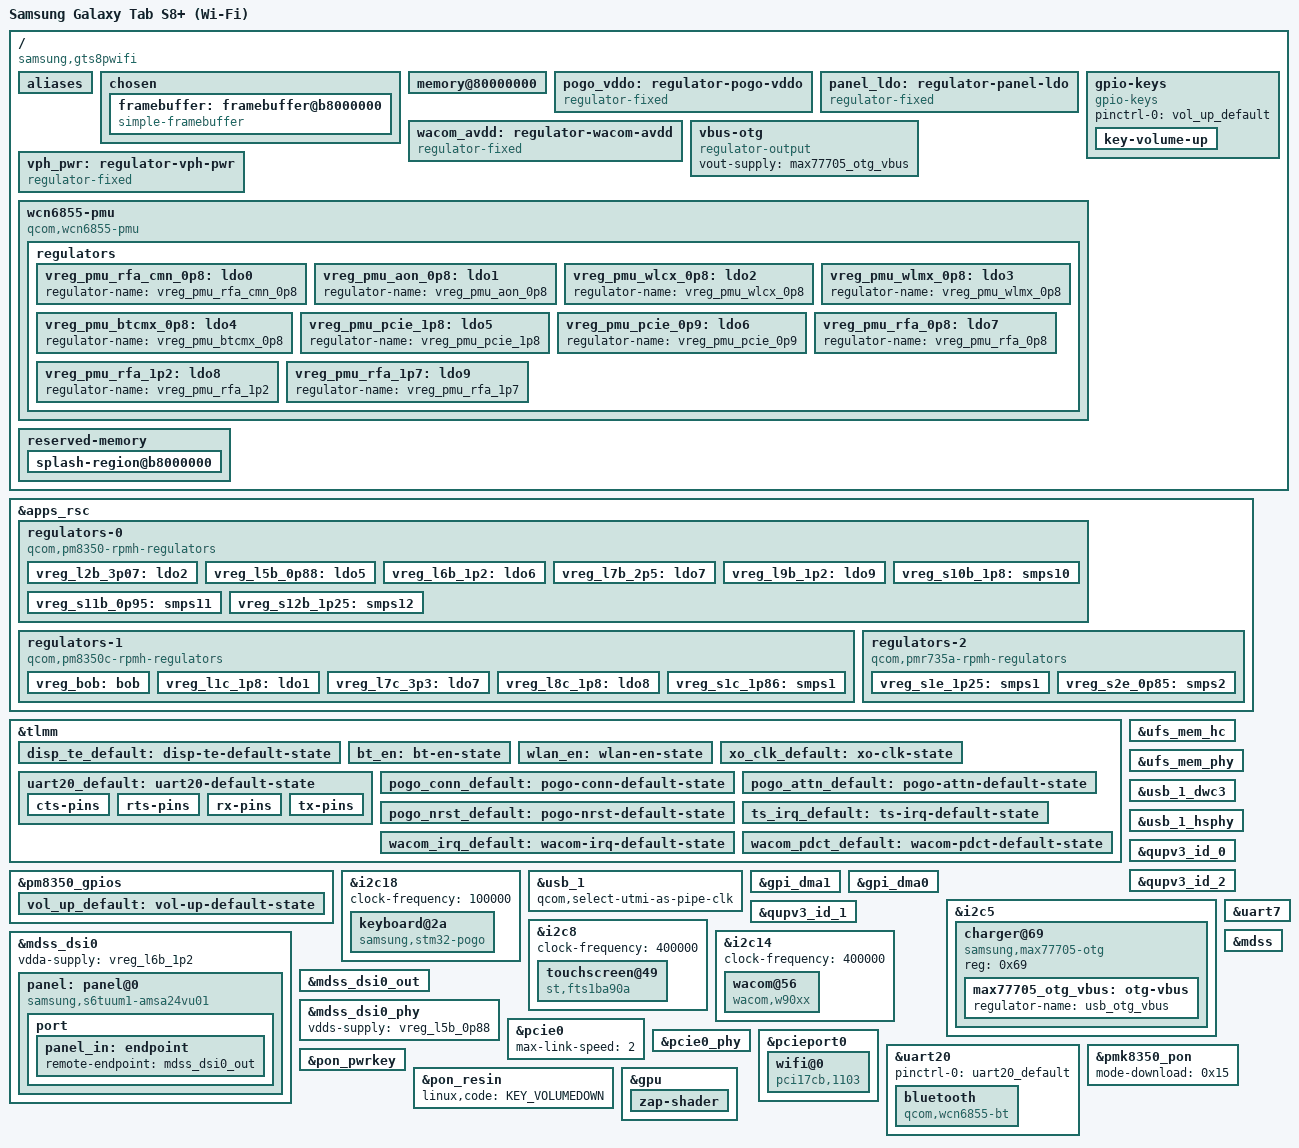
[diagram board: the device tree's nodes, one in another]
// SPDX-License-Identifier: GPL-2.0-only
/*
 * Samsung Galaxy Tab S8+ Wi-Fi (SM-X800), codename "gts8pwifi".
 *
 * SM8450 (Waipio). First-boot bring-up skeleton derived from
 * sm8450-samsung-r0q.dts (Galaxy S22). The bootloader (Samsung ABL)
 * leaves the panel scanning out of the "splash_region" at 0xb8000000,
 * so a matching simple-framebuffer node gives us a VISIBLE fbcon console
 * on the panel before any real DRM driver exists. This is the whole
 * point of the mainline pivot (see docs/discovery-notes/04-mainline-prep.md).
 *
 * Framebuffer geometry pulled from the stock DTB:
 *   splash reserved-memory  = <0x0 0xb8000000 0x0 0x2b00000> (45 MiB)
 *   panel active (touch max) = 1752 x 2800 (0x6d8 x 0xaf0), portrait scanout
 *   DDIC S6TUUM1_AMSA24VU01_WQXGA, lcd_id 800005 (native driver = later)
 */

/dts-v1/;

#include <dt-bindings/gpio/gpio.h>
#include <dt-bindings/input/linux-event-codes.h>
#include <dt-bindings/interrupt-controller/irq.h>
#include <dt-bindings/regulator/qcom,rpmh-regulator.h>

#include "sm8450.dtsi"
#include "pm8350.dtsi"
#include "pm8350c.dtsi"
/* pmk8350 carries the power key + resin (volume down) — see &pon_* below */
#include "pmk8350.dtsi"

/ {
	model = "Samsung Galaxy Tab S8+ (Wi-Fi)";
	compatible = "samsung,gts8pwifi", "qcom,sm8450";
	chassis-type = "tablet";

	/*
	 * Samsung's Qualcomm bootloader (ABL) runs DTB selection: it only
	 * boots a DTB whose qcom,msm-id (SoC id+rev) and qcom,board-id match
	 * the running hardware. Mainline DTs omit these, so ABL found no match
	 * and jumped to the kernel with no device tree -> early death, no
	 * simplefb, fall back to download mode. These values are copied
	 * verbatim from the stock DTB (device-facts/dt/stock-fdt.dtb). The
	 * kernel ignores them; they exist purely for the bootloader.
	 */
	qcom,msm-id = <0x1c9 0x10000>, <0x1e2 0x10000>;
	qcom,board-id = <0x10008 0x04>;

	/*
	 * qcom_geni_serial derives its tty line number from these aliases and
	 * fails probe with "Invalid line -19" without one. That silently broke
	 * BOTH uarts: uart7 (debug, has been failing since bring-up — earlycon
	 * worked because it bypasses the tty layer) and uart20, whose failed
	 * probe also held four interconnect providers' sync_state() hostage
	 * (the i2c8 lesson again) and kept the wcn6855-bt serdev child from
	 * ever binding.
	 */
	aliases {
		serial0 = &uart7;
		serial1 = &uart20;
	};

	chosen {
		#address-cells = <2>;
		#size-cells = <2>;
		ranges;

		/*
		 * We boot via uniLoader (the Samsung ABL mangles mainline DTs
		 * with its own DTBO fragments, so a direct ABL boot cannot
		 * work here — see docs/05). uniLoader only injects
		 * linux,initrd-start/end into /chosen; it does NOT set
		 * bootargs. So the kernel command line has to live here, or we
		 * would silently inherit the stock vendor_boot cmdline
		 * (console=null) and be blind again.
		 *
		 * LAYOUT: userdata holds the COMBINED pmOS image (`pmb install`
		 * WITHOUT --split), i.e. a GPT containing BOTH pmOS_boot and
		 * pmOS_root as "subpartitions". That is required: the pmOS
		 * initramfs does mount_subpartitions -> wait_boot_partition ->
		 * mount_boot_partition, so it needs a pmOS_boot too, and our
		 * real boot partition is occupied by uniLoader. Flashing only
		 * the --split -root.img leaves no boot partition and the
		 * initramfs falls to the debug shell.
		 *
		 * Both UUIDs must match the image actually flashed to userdata.
		 * NOTE: re-running `pmb install` regenerates them — read the
		 * fresh values out of boot-deploy's cmdline:
		 *   strings <pmb-work>/chroot_rootfs_<device>/boot/vendor_boot.img
		 *     | grep pmos_root_uuid
		 */
		/*
		 * NOTE: console=ttyMSM0 was REMOVED. uart7 is enabled (so the
		 * port exists and earlycon still works), but with no cable
		 * attached its RX line floats and picks up noise. getty reads
		 * that noise as input and re-prints the login prompt forever,
		 * which also corrupts the framebuffer console we actually use.
		 * Put console=ttyMSM0,115200n8 back only when something is
		 * physically wired to the UART.
		 *
		 * clk_ignore_unused / pd_ignore_unused are REQUIRED to keep the
		 * panel alive. The bootloader leaves the display clocks and
		 * power domains running so the cont_splash framebuffer keeps
		 * scanning out. Late in boot the kernel disables everything it
		 * believes is unused — there is no real display driver here to
		 * claim them — which gates the display clocks and the panel
		 * goes BLACK mid-boot, even though the kernel is still running
		 * happily. Observed exactly that: boot log painted, then black.
		 */
		/*
		 * r40: clk_ignore_unused / pd_ignore_unused RETIRED. They were
		 * required in the simpledrm era (see the note above — nothing
		 * claimed the display clocks). Now the msm DPU/DSI/panel and
		 * GPU drivers own their clocks and domains; keeping every
		 * unclaimed clock/GDSC on forever costs power and masks real
		 * PM bugs. If this boot regresses, the failing subsystem is
		 * whatever still lacks a driver to claim its resources.
		 */
		/*
		 * r41: loglevel=8 ignore_loglevel -> loglevel=4. Bring-up-era
		 * verbosity put EVERY printk on the panel; in steady state the
		 * wlan0 chatter alone stomped agetty into endlessly re-printing
		 * "login:" (photo-verified). Warnings and errors still reach
		 * the console; everything lands in the persistent journal.
		 */
		bootargs = "earlycon=qcom_geni,0x0099c000 console=tty0 fbcon=font:TER16x32 loglevel=4 arm-smmu.disable_bypass=0 PMOS_NO_OUTPUT_REDIRECT pmos_boot_uuid=a52ecfd9-ba7c-4c8e-a80f-d6341ef93081 pmos_root_uuid=ae56a720-d465-46c7-9e43-ecbd33124aa9 pmos_rootfsopts=defaults";

		framebuffer: framebuffer@b8000000 {
			compatible = "simple-framebuffer";
			reg = <0x0 0xb8000000 0x0 0x2b00000>;
			/*
			 * LANDSCAPE scanout: 2800 wide x 1752 tall. Confirmed
			 * on-device — using 1752x2800 rendered diagonally
			 * sheared text. Stock panel physical size is
			 * 267mm x 167mm (ratio 1.60 == 2800/1752), so the long
			 * axis is the scanline. The touchscreen's
			 * sec,max_coords <0x6d8 0xaf0> is a portrait touch
			 * coordinate space and does NOT describe scanout.
			 */
			width = <2800>;
			height = <1752>;
			stride = <(2800 * 4)>;
			format = "a8r8g8b8";

			/*
			 * simpledrm acquires and HOLDS these across boot (see
			 * simpledrm_device_release_clocks / _detach_genpd in
			 * the kernel). Without them nothing keeps the display
			 * block alive: the bootloader's scanout gets torn down
			 * and the framebuffer degenerates into ordinary RAM,
			 * which renders on-panel as accumulating garbage.
			 * Clock/GDSC references taken from the mdss node in
			 * mainline sm8450.dtsi.
			 */
			clocks = <&dispcc DISP_CC_MDSS_AHB_CLK>,
				 <&gcc GCC_DISP_HF_AXI_CLK>,
				 <&gcc GCC_DISP_SF_AXI_CLK>,
				 <&dispcc DISP_CC_MDSS_MDP_CLK>,
				 <&dispcc DISP_CC_MDSS_VSYNC_CLK>;
			power-domains = <&dispcc MDSS_GDSC>;
		};
	};

	/*
	 * sm8450.dtsi ships a placeholder memory@a0000000 with reg size 0,
	 * on the assumption that the bootloader patches in the real banks.
	 * uniLoader does NOT do that (it only injects linux,initrd-start/end
	 * into /chosen), so the kernel would be handed ZERO bytes of RAM and
	 * panic instantly, before any console exists — a completely silent
	 * hang right after uniLoader prints "Booting kernel...".
	 *
	 * Banks copied verbatim from the stock DTB (device-facts/dt/stock-fdt.dtb),
	 * total 8 GiB.
	 */
	/delete-node/ memory@a0000000;

	memory@80000000 {
		device_type = "memory";
		reg = <0x0 0x80000000 0x0 0x6a000000>,
		      <0x0 0xf1c00000 0x0 0x0e400000>,
		      <0x8 0x00000000 0x0 0x3ab00000>,
		      <0x8 0x40000000 0x1 0x40000000>,
		      <0x8 0x3b100000 0x0 0x01e00000>;
	};

	/*
	 * Pogo/Book-Cover-Keyboard STM32 supply. Stock models this as a plain
	 * GPIO-switched fixed regulator (not a PMIC rail): gpio70, active high.
	 * Gated by the stm32-pogo driver: on at dock, off at detach — always-on
	 * was a bring-up crutch and is gone now that the driver owns the rail.
	 */
	pogo_vddo: regulator-pogo-vddo {
		compatible = "regulator-fixed";
		regulator-name = "pogo_vddo";
		gpio = <&tlmm 70 GPIO_ACTIVE_HIGH>;
		enable-active-high;
	};

	/*
	 * Panel power. Stock models the OLED's supply as a GPIO-switched
	 * external LDO (fixed_regulator@1 "panel_ldo_en", tlmm 34), boot-on —
	 * which is why the bootloader splash survives to this day. The panel
	 * driver consumes it as vdd; boot-on keeps the handoff glitch-free.
	 */
	panel_ldo: regulator-panel-ldo {
		compatible = "regulator-fixed";
		regulator-name = "panel_ldo_en";
		gpio = <&tlmm 34 GPIO_ACTIVE_HIGH>;
		enable-active-high;
		regulator-boot-on;
	};

	/*
	 * S Pen (Wacom W90xx EMR digitizer) AVDD. Stock models it as a
	 * GPIO-switched fixed regulator (fixed_regulator0, tlmm 167, active
	 * high). regulator-always-on for now: the pen has no mainline driver
	 * yet, so nothing else would enable the rail — always-on lets the chip
	 * power up so its i2c presence (0x56 on &i2c14) can be probed. Once a
	 * wacom driver lands it should own this rail (drop always-on), the way
	 * the stm32-pogo driver took over pogo_vddo.
	 */
	wacom_avdd: regulator-wacom-avdd {
		compatible = "regulator-fixed";
		regulator-name = "wacom_avdd";
		gpio = <&tlmm 167 GPIO_ACTIVE_HIGH>;
		enable-active-high;
		regulator-always-on;
		regulator-boot-on;
	};

	/*
	 * Manual switch for tablet-sourced USB VBUS (the MAX77705 OTG boost,
	 * see charger@69). regulator-output is the mainline convention for a
	 * userspace-switched rail: it surfaces
	 *     /sys/devices/platform/vbus-otg/state
	 * (helper: `vbus-otg on|off`). Default off; the driver refuses to
	 * enable while a charger input is present. Automatic switching is
	 * Type-C/TCPM territory — a later increment.
	 */
	vbus-otg {
		compatible = "regulator-output";
		vout-supply = <&max77705_otg_vbus>;
	};

	/*
	 * Volume UP + pogo attach detection.
	 *
	 * Volume up is the odd one out on this device: power and volume-DOWN
	 * live in the pmk8350 PON block (&pon_pwrkey / &pon_resin), but stock
	 * wires volume-UP as a plain gpio-keys line on a pm8350 PMIC GPIO,
	 * active LOW with a pull-up. Stock DTB:
	 *     vol_up { gpios = <0x540 0x06 0x01>; linux,code = <0x73>; }
	 * where phandle 0x540 is qcom,pm8350-gpio @0x8800 and 0x01 = ACTIVE_LOW.
	 *
	 * STATUS: dead, and NOT an index problem. Measured on-device (r38,
	 * 2026-07-20): with gpio-keys unbound, gpiomon watched every line of
	 * pm8350/pm8350c/pmk8350 through repeated vol-up presses — zero edges
	 * anywhere. Line 5 (= this cell 6) idles high like a pulled-up button
	 * but never drops on press. Stock DTB has exactly one vol-up wiring
	 * (this one), so the next step is schematic-level: check the pull-up
	 * power-source rail, or poke the pm8350 gpio6 status register over
	 * SPMI debugfs while pressing. Do NOT bother permuting cell numbers;
	 * that experiment is done.
	 */
	gpio-keys {
		compatible = "gpio-keys";
		pinctrl-names = "default";
		pinctrl-0 = <&vol_up_default>;

		key-volume-up {
			label = "Volume Up";
			gpios = <&pm8350_gpios 6 GPIO_ACTIVE_LOW>;
			linux,code = <KEY_VOLUMEUP>;
			debounce-interval = <15>;
			wakeup-source;
		};

		/*
		 * The switch-pogo-attach EV_SW debug node that used to live
		 * here is gone: the stm32-pogo driver now owns tlmm gpio59 as
		 * its connection interrupt (a GPIO cannot be claimed by both).
		 * The pogo pinctrl states moved to the keyboard@2a node with
		 * it.
		 */
	};

	vph_pwr: regulator-vph-pwr {
		compatible = "regulator-fixed";
		regulator-name = "vph_pwr";
		regulator-min-microvolt = <3700000>;
		regulator-max-microvolt = <3700000>;
		regulator-always-on;
		regulator-boot-on;
	};

	/*
	 * WiFi/BT: QCA6490 (= WCN6855 family), WiFi on PCIe0 via ath11k, BT
	 * on uart20. Near-copy of sm8450-hdk.dts, and legitimately so: the
	 * stock DTB's cnss-qca6490/bt_qca6490 nodes use the exact same
	 * enable GPIOs (wlan 80, bt 81, sw-ctrl 82, xo-clk 204) and the same
	 * PMIC rails as the HDK — both boards follow the QC reference
	 * design. Rail cross-check stock -> mainline:
	 *   vdd-wlan-io   pm8350_s10  1.8 V   -> vddio   (vreg_s10b_1p8)
	 *   vdd-wlan-dig  pm8350_s11  0.966 V -> vddaon/vddpmucx/vddrfa0p95
	 *   vdd-wlan-rfa1 pm8350c_s1  1.9-2.1 -> vddrfa1p9 (vreg_s1c_1p86)
	 *   vdd-wlan-rfa2 pm8350_s12  1.35 V  -> vddrfa1p3 (vreg_s12b_1p25)
	 *   vdd-wlan-aon  pmr735a_s2  1.012 V -> vddpmumx  (vreg_s2e_0p85)
	 * Stock also lists a wlan-ant-switch supply (pmr735a_l7, 2.8 V), but
	 * there is no physical antenna switch on this tablet (owner-confirmed)
	 * — a copy-paste from the QC reference DT. Deliberately not wired; do
	 * not chase it for RF issues.
	 */
	wcn6855-pmu {
		compatible = "qcom,wcn6855-pmu";

		pinctrl-0 = <&bt_en>, <&wlan_en>, <&xo_clk_default>;
		pinctrl-names = "default";

		wlan-enable-gpios = <&tlmm 80 GPIO_ACTIVE_HIGH>;
		bt-enable-gpios = <&tlmm 81 GPIO_ACTIVE_HIGH>;
		swctrl-gpios = <&tlmm 82 GPIO_ACTIVE_HIGH>;
		xo-clk-gpios = <&tlmm 204 GPIO_ACTIVE_HIGH>;

		vddio-supply = <&vreg_s10b_1p8>;
		vddaon-supply = <&vreg_s11b_0p95>;
		vddpmu-supply = <&vreg_s12b_1p25>;
		vddpmumx-supply = <&vreg_s2e_0p85>;
		vddpmucx-supply = <&vreg_s11b_0p95>;
		vddrfa0p95-supply = <&vreg_s11b_0p95>;
		vddrfa1p3-supply = <&vreg_s12b_1p25>;
		vddrfa1p9-supply = <&vreg_s1c_1p86>;
		vddpcie1p3-supply = <&vreg_s12b_1p25>;
		vddpcie1p9-supply = <&vreg_s1c_1p86>;

		regulators {
			vreg_pmu_rfa_cmn_0p8: ldo0 {
				regulator-name = "vreg_pmu_rfa_cmn_0p8";
			};

			vreg_pmu_aon_0p8: ldo1 {
				regulator-name = "vreg_pmu_aon_0p8";
			};

			vreg_pmu_wlcx_0p8: ldo2 {
				regulator-name = "vreg_pmu_wlcx_0p8";
			};

			vreg_pmu_wlmx_0p8: ldo3 {
				regulator-name = "vreg_pmu_wlmx_0p8";
			};

			vreg_pmu_btcmx_0p8: ldo4 {
				regulator-name = "vreg_pmu_btcmx_0p8";
			};

			vreg_pmu_pcie_1p8: ldo5 {
				regulator-name = "vreg_pmu_pcie_1p8";
			};

			vreg_pmu_pcie_0p9: ldo6 {
				regulator-name = "vreg_pmu_pcie_0p9";
			};

			vreg_pmu_rfa_0p8: ldo7 {
				regulator-name = "vreg_pmu_rfa_0p8";
			};

			vreg_pmu_rfa_1p2: ldo8 {
				regulator-name = "vreg_pmu_rfa_1p2";
			};

			vreg_pmu_rfa_1p7: ldo9 {
				regulator-name = "vreg_pmu_rfa_1p7";
			};
		};
	};

	reserved-memory {
		/*
		 * The bootloader will only keep display hardware enabled
		 * if this memory region is named exactly 'splash_region'
		 */
		splash-region@b8000000 {
			reg = <0x0 0xb8000000 0x0 0x2b00000>;
			no-map;
		};
	};
};

&apps_rsc {
	regulators-0 {
		compatible = "qcom,pm8350-rpmh-regulators";
		qcom,pmic-id = "b";

		vdd-s1-supply = <&vph_pwr>;
		vdd-s2-supply = <&vph_pwr>;
		vdd-s3-supply = <&vph_pwr>;
		vdd-s4-supply = <&vph_pwr>;
		vdd-s5-supply = <&vph_pwr>;
		vdd-s6-supply = <&vph_pwr>;
		vdd-s7-supply = <&vph_pwr>;
		vdd-s8-supply = <&vph_pwr>;
		vdd-s9-supply = <&vph_pwr>;
		vdd-s10-supply = <&vph_pwr>;
		vdd-s11-supply = <&vph_pwr>;
		vdd-s12-supply = <&vph_pwr>;

		vdd-l2-l7-supply = <&vreg_bob>;
		vdd-l3-l5-supply = <&vreg_bob>;
		vdd-l6-l9-l11-supply = <&vreg_bob>;

		vreg_l2b_3p07: ldo2 {
			regulator-min-microvolt = <3072000>;
			regulator-max-microvolt = <3072000>;
			regulator-initial-mode = <RPMH_REGULATOR_MODE_HPM>;
		};

		vreg_l5b_0p88: ldo5 {
			regulator-min-microvolt = <880000>;
			regulator-max-microvolt = <888000>;
			regulator-initial-mode = <RPMH_REGULATOR_MODE_HPM>;
		};

		/* UFS rails (l6b/l7b/l9b) — see &ufs_mem_hc below */
		vreg_l6b_1p2: ldo6 {
			regulator-name = "vreg_l6b_1p2";
			regulator-min-microvolt = <1200000>;
			regulator-max-microvolt = <1200000>;
			regulator-initial-mode = <RPMH_REGULATOR_MODE_HPM>;
		};

		vreg_l7b_2p5: ldo7 {
			regulator-name = "vreg_l7b_2p5";
			regulator-min-microvolt = <2504000>;
			regulator-max-microvolt = <2504000>;
			regulator-initial-mode = <RPMH_REGULATOR_MODE_HPM>;
		};

		vreg_l9b_1p2: ldo9 {
			regulator-name = "vreg_l9b_1p2";
			regulator-min-microvolt = <1200000>;
			regulator-max-microvolt = <1200000>;
			regulator-initial-mode = <RPMH_REGULATOR_MODE_HPM>;
		};

		/* WCN6855 (WiFi/BT) rails — see the wcn6855-pmu node */
		vreg_s10b_1p8: smps10 {
			regulator-name = "vreg_s10b_1p8";
			regulator-min-microvolt = <1800000>;
			regulator-max-microvolt = <1800000>;
		};

		vreg_s11b_0p95: smps11 {
			regulator-name = "vreg_s11b_0p95";
			regulator-min-microvolt = <966000>;
			regulator-max-microvolt = <1104000>;
		};

		vreg_s12b_1p25: smps12 {
			regulator-name = "vreg_s12b_1p25";
			regulator-min-microvolt = <1350000>;
			regulator-max-microvolt = <1400000>;
		};
	};

	regulators-1 {
		compatible = "qcom,pm8350c-rpmh-regulators";
		qcom,pmic-id = "c";

		vdd-s1-supply = <&vph_pwr>;
		vdd-s2-supply = <&vph_pwr>;
		vdd-s3-supply = <&vph_pwr>;
		vdd-s4-supply = <&vph_pwr>;
		vdd-s5-supply = <&vph_pwr>;
		vdd-s6-supply = <&vph_pwr>;
		vdd-s7-supply = <&vph_pwr>;
		vdd-s8-supply = <&vph_pwr>;
		vdd-s9-supply = <&vph_pwr>;
		vdd-s10-supply = <&vph_pwr>;

		vdd-l1-l12-supply = <&vreg_bob>;
		vdd-l2-l8-supply = <&vreg_bob>;
		vdd-l3-l4-l5-l7-l13-supply = <&vreg_bob>;
		vdd-l6-l9-l11-supply = <&vreg_bob>;

		vdd-bob-supply = <&vph_pwr>;

		vreg_bob: bob {
			regulator-min-microvolt = <3008000>;
			regulator-max-microvolt = <3960000>;
			regulator-initial-mode = <RPMH_REGULATOR_MODE_AUTO>;
		};

		vreg_l1c_1p8: ldo1 {
			regulator-min-microvolt = <1800000>;
			regulator-max-microvolt = <1800000>;
			regulator-initial-mode = <RPMH_REGULATOR_MODE_HPM>;
		};

		/*
		 * Touchscreen rails, from the stock DTB's touchscreen@49:
		 *   tsp_avdd_ldo-supply -> pm8350c L7C, 3.3 V,     regulator-boot-on
		 *   tsp_io_ldo-supply   -> pm8350c L8C, 1.848 V,   regulator-boot-on
		 * Parent supplies are already declared above (l7 via
		 * vdd-l3-l4-l5-l7-l13, l8 via vdd-l2-l8).
		 */
		vreg_l7c_3p3: ldo7 {
			/*
			 * Measured on-device: vreg_bob runs at 3.032 V, and this
			 * LDO is parented to it (vdd-l3-l4-l5-l7-l13-supply).
			 * A fixed 3.3 V request cannot be satisfied from a
			 * 3.03 V input, so allow a range instead of pinning it.
			 */
			regulator-min-microvolt = <3000000>;
			regulator-max-microvolt = <3300000>;
			regulator-initial-mode = <RPMH_REGULATOR_MODE_HPM>;
		};

		vreg_l8c_1p8: ldo8 {
			regulator-min-microvolt = <1848000>;
			regulator-max-microvolt = <1848000>;
			regulator-initial-mode = <RPMH_REGULATOR_MODE_HPM>;
		};

		/* WCN6855 rfa 1.9 V rail (stock vdd-wlan-rfa1) */
		vreg_s1c_1p86: smps1 {
			regulator-name = "vreg_s1c_1p86";
			regulator-min-microvolt = <1800000>;
			regulator-max-microvolt = <2024000>;
		};
	};

	/*
	 * pmr735a, the RF PMIC. Declared for the WCN6855 rails only: s2e is
	 * stock's vdd-wlan-aon (pmr735a_s2, 1.012 V). s1e parents l3e in the
	 * HDK layout and is kept for that supply topology.
	 */
	regulators-2 {
		compatible = "qcom,pmr735a-rpmh-regulators";
		qcom,pmic-id = "e";

		vdd-s1-supply = <&vph_pwr>;
		vdd-s2-supply = <&vph_pwr>;
		vdd-s3-supply = <&vph_pwr>;

		vdd-l1-l2-supply = <&vreg_s2e_0p85>;
		vdd-l3-supply = <&vreg_s1e_1p25>;
		vdd-l4-supply = <&vreg_s1c_1p86>;
		vdd-l5-l6-supply = <&vreg_s1c_1p86>;
		vdd-l7-bob-supply = <&vreg_bob>;

		vreg_s1e_1p25: smps1 {
			regulator-name = "vreg_s1e_1p25";
			regulator-min-microvolt = <1200000>;
			regulator-max-microvolt = <1296000>;
		};

		vreg_s2e_0p85: smps2 {
			regulator-name = "vreg_s2e_0p85";
			regulator-min-microvolt = <500000>;
			regulator-max-microvolt = <1040000>;
		};
	};
};

&tlmm {
	gpio-reserved-ranges = <36 4>; /* SPI (not linked to anything) */

	/*
	 * nrst (gpio97) is owned by the stm32-pogo driver (nrst-gpios): held
	 * high, pulsed low to recover a wedged MCU after an i2c failure —
	 * which is why it must not be a gpio-hog (a hog can never pulse).
	 * pogo_nrst_default still drives it high from boot so the MCU is out
	 * of reset before the driver probes. Line names kept for gpioinfo.
	 */
	gpio-line-names =
		"", "", "", "", "", "", "", "", "", "",		/*  0-9  */
		"", "", "", "", "", "", "", "", "", "",		/* 10-19 */
		"", "", "", "", "", "", "", "", "", "",		/* 20-29 */
		"", "", "", "", "", "", "", "", "", "",		/* 30-39 */
		"", "", "", "", "", "", "", "", "", "",		/* 40-49 */
		"", "", "", "", "", "", "", "", "",		/* 50-58 */
		"pogo-conn-detect",				/* 59 */
		"", "", "", "", "", "", "", "", "", "",		/* 60-69 */
		"pogo-vddo-en",					/* 70 */
		"pogo-stm32-attn",				/* 71 */
		"", "", "", "", "", "", "", "", "",		/* 72-80 */
		"", "", "", "", "", "", "", "", "", "",		/* 81-90 */
		"", "", "", "", "", "",				/* 91-96 */
		"pogo-stm32-nrst",				/* 97 */
		"",						/* 98 */
		"pogo-stm32-swclk";				/* 99 */

	/*
	 * Pogo pinctrl, transcribed from the stock DTB (nodes attn_irq,
	 * conn_irq, nrst_gpio — all tlmm, all drive-strength 2, bias-disable).
	 * Without these the pins keep whatever mux/bias the bootloader left,
	 * which for conn-detect means the level we read may be meaningless.
	 */
	/* Panel TE (tear enable), stock sde_te on gpio86, mdp_vsync function */
	disp_te_default: disp-te-default-state {
		pins = "gpio86";
		function = "mdp_vsync";
		drive-strength = <2>;
		bias-pull-down;
	};

	/* WCN6855 enable lines + BT UART, values as HDK (stock GPIOs match) */
	bt_en: bt-en-state {
		pins = "gpio81";
		function = "gpio";
		drive-strength = <16>;
		output-low;
		bias-pull-down;
	};

	wlan_en: wlan-en-state {
		pins = "gpio80";
		function = "gpio";
		drive-strength = <16>;
		output-low;
		bias-pull-down;
	};

	xo_clk_default: xo-clk-state {
		pins = "gpio204";
		function = "gpio";
		drive-strength = <16>;
		output-low;
		bias-pull-down;
	};

	uart20_default: uart20-default-state {
		cts-pins {
			pins = "gpio76";
			function = "qup20";
			bias-disable;
		};

		rts-pins {
			pins = "gpio77";
			function = "qup20";
			bias-disable;
		};

		rx-pins {
			pins = "gpio78";
			function = "qup20";
			bias-disable;
		};

		tx-pins {
			pins = "gpio79";
			function = "qup20";
			bias-disable;
		};
	};

	pogo_conn_default: pogo-conn-default-state {
		pins = "gpio59";		/* stm32,irq_conn */
		function = "gpio";
		drive-strength = <2>;
		bias-disable;
		input-enable;
	};

	pogo_attn_default: pogo-attn-default-state {
		pins = "gpio71";		/* stm32,irq_gpio (attn) */
		function = "gpio";
		drive-strength = <2>;
		bias-disable;
		input-enable;
	};

	pogo_nrst_default: pogo-nrst-default-state {
		pins = "gpio97";		/* stm32,mcu_nrst */
		function = "gpio";
		drive-strength = <2>;
		bias-disable;
		output-high;
	};

	/*
	 * Touchscreen attention/IRQ line. Transcribed from the stock
	 * fts1ba90a_attn_irq state (the "on_state"); stock also has an
	 * fts1ba90a_attn_irq_suspend variant that only swaps bias-disable for
	 * bias-pull-down, which we do not need without runtime PM.
	 * No drive-strength is set in stock either.
	 */
	ts_irq_default: ts-irq-default-state {
		pins = "gpio46";		/* sec,irq_gpio */
		function = "gpio";
		bias-disable;
		input-enable;
	};

	/*
	 * S Pen (Wacom) lines, from the stock epen-int-active / epen-pdct-active
	 * states: both inputs, bias-disable. The fwe line (gpio54) is driven by
	 * the driver directly, so it gets no pin state here.
	 */
	wacom_irq_default: wacom-irq-default-state {
		pins = "gpio51";		/* wacom,irq-gpio (epen-int) */
		function = "gpio";
		bias-disable;
		input-enable;
	};

	wacom_pdct_default: wacom-pdct-default-state {
		pins = "gpio155";		/* wacom,pdct-gpio (epen-pdct) */
		function = "gpio";
		bias-disable;
		input-enable;
	};
};

/*
 * Volume-up pin on the pm8350. Stock state (key_vol_up_default):
 *     pins = "gpio6"; function = "normal";
 *     input-enable; bias-pull-up; power-source = <1>;
 */
&pm8350_gpios {
	vol_up_default: vol-up-default-state {
		pins = "gpio6";
		function = "normal";
		power-source = <1>;
		bias-pull-up;
		input-enable;
	};
};

/*
 * Book Cover Keyboard (EF-DT970 / EF-DT730 "Slim"), our stm32-pogo driver
 * (staged into drivers/input/keyboard/ by the kernel APKBUILD).
 *
 * The keyboard does not talk to the SoC directly: an STM32G0 MCU in the
 * keyboard scans the matrix and speaks a proprietary Samsung/ST protocol at
 * I2C 0x2a on QUP se18. It is NOT HID-over-I2C. The investigation history
 * (14 ruled-out hypotheses) is in tools/README.md; the punchline is that
 * the MCU only serves 0x2a as part of an interrupt-driven handshake the
 * host must complete — 12k userspace probes could never see it. The
 * handshake itself is documented at the top of stm32-pogo.c.
 *
 * All values here are from the stock DTB (stm32@2a node). Mainline i2c18
 * is verified to be the same controller: stock reg 0x88c000 == mainline
 * i2c@88c000, stock sda/scl gpio68/69 == qup_i2c18_data_clk.
 *   stm32,irq_conn  <&tlmm 59>  -> conn-gpios  (dock detect, edge both)
 *   stm32,irq_gpio  <&tlmm 71>  -> attn-gpios  (MCU event line, level low)
 *   stm32,mcu_nrst  <&tlmm 97>  -> nrst-gpios  (held high; pulsed to
 *                                  recover a wedged MCU on i2c failure)
 *   stm32_vddo-supply           -> vdd-supply  (gpio70 fixed regulator)
 * stm32,mcu_swclk (gpio99) is deliberately not claimed: it is only used by
 * the downstream firmware-update path, which we did not port. It stays
 * free for the ROM-bootloader dump tooling (tools/pogo-stm32-*.sh).
 */
&i2c18 {
	/*
	 * Stock sets no qcom,clk-freq-out, so the controller default applies.
	 * 100 kHz was chosen for the detection probes and has proven solid;
	 * the protocol is low-bandwidth (16-byte-ish events), so there is no
	 * reason to push it.
	 */
	clock-frequency = <100000>;
	status = "okay";

	keyboard@2a {
		compatible = "samsung,stm32-pogo";
		reg = <0x2a>;

		pinctrl-names = "default";
		pinctrl-0 = <&pogo_conn_default>,
			    <&pogo_attn_default>,
			    <&pogo_nrst_default>;

		vdd-supply = <&pogo_vddo>;
		conn-gpios = <&tlmm 59 GPIO_ACTIVE_HIGH>;
		attn-gpios = <&tlmm 71 GPIO_ACTIVE_HIGH>;
		nrst-gpios = <&tlmm 97 GPIO_ACTIVE_HIGH>;
	};
};

/*
 * UFS — the internal storage. Without this there are NO block devices at all,
 * so the pmOS initramfs cannot find the rootfs and drops to the debug shell
 * with "ERROR: failed to mount subpartitions!". Neither r0q.dts nor our
 * original skeleton enabled it. Supplies follow sm8450-hdk.dts.
 *
 * reset-gpios is deliberately omitted: the HDK's <&tlmm 210> is board
 * specific and the stock DTB exposes no UFS reset line for this tablet.
 */
&ufs_mem_hc {
	status = "okay";

	vcc-supply = <&vreg_l7b_2p5>;
	vcc-max-microamp = <1100000>;
	vccq-supply = <&vreg_l9b_1p2>;
	vccq-max-microamp = <1200000>;
	vdd-hba-supply = <&vreg_l9b_1p2>;
};

&ufs_mem_phy {
	status = "okay";

	vdda-phy-supply = <&vreg_l5b_0p88>;
	vdda-pll-supply = <&vreg_l6b_1p2>;
};

/*
 * USB — gadget only, USB 2.0 only.
 *
 * IMPORTANT: sm8450-mainline's sm8450.dtsi uses the SPLIT dwc3 binding —
 *   usb_1:      usb@a6f8800  "qcom,sm8450-dwc3"  (Qualcomm glue/wrapper)
 *   usb_1_dwc3: usb@a600000  "snps,dwc3"         (the actual core)
 * Properties like dr_mode / phys / maximum-speed belong on the CORE node.
 * Setting them on the wrapper (as sm8450-samsung-r0q.dts does) silently does
 * nothing here. Note that upstream torvalds has since MERGED these into one
 * node, so DTS snippets copied from mainline devices will not match this tree.
 *
 * Two separate things are needed for USB2-only operation:
 *
 * 1. Remove usb_1_qmpphy from the CORE's phys list. Do not rely on leaving it
 *    status="disabled": _of_phy_get() looks the provider up BEFORE checking
 *    availability, so a disabled phy whose driver never bound returns
 *    -EPROBE_DEFER forever rather than the graceful "Requested PHY is
 *    disabled" -> -ENODEV path. Only dropping the phandle gives a clean NULL
 *    and lets dwc3 probe. Symptom of getting this wrong:
 *      platform a600000.usb: deferred probe pending: dwc3: failed to initialize core
 *
 * 2. qcom,select-utmi-as-pipe-clk on the GLUE node (below). With the
 *    SuperSpeed phy gone there is no pipe clock, so the qcom glue must be told
 *    to clock from UTMI instead.
 *
 * NOTE: "dwc3 a600000.usb: Configuration mismatch. dr_mode forced to gadget"
 * is NOT an error. With no extcon and no usb-role-switch, dwc3_get_dr_mode()
 * degrades OTG->PERIPHERAL and logs that — i.e. it settled on gadget, which is
 * what we want. Do NOT add usb-role-switch to "fix" it; that is only needed
 * for dr_mode="otg".
 *
 * The split binding is the ONLY one this kernel supports: dwc3_qcom_of_match[]
 * has just "qcom,dwc3", and dwc3_qcom_of_register_core() hard-fails without a
 * "snps,dwc3" child. Bjorn Andersson's flatten series landed in v6.16, so
 * never backport a flattened single-node USB DTS into this tree.
 */
&usb_1 {
	/*
	 * Required for USB2-only: with usb_1_qmpphy out of the picture there is
	 * no SuperSpeed pipe clock, so the glue must source from UTMI instead.
	 */
	qcom,select-utmi-as-pipe-clk;

	status = "okay";
};

&usb_1_dwc3 {
	/*
	 * PERIPHERAL (gadget) mode.
	 *
	 * Host mode was tried so a USB keyboard could be used for input, and it
	 * cannot work here: in host mode the tablet has to supply 5V VBUS to the
	 * peripheral, and VBUS is switched by the Type-C/PMIC (pmic_glink),
	 * which this DTS does not describe. A bus-powered keyboard therefore
	 * never gets power and never enumerates, no matter what dwc3 does.
	 *
	 * In peripheral mode the HOST supplies VBUS, so no Type-C support is
	 * needed — which also makes this the path to USB networking / SSH.
	 * Revisit "host"/"otg" only after pmic_glink + Type-C are described.
	 */
	/*
	 * HOST mode, for use with an EXTERNALLY POWERED USB-C dongle/hub.
	 *
	 * Plain host mode failed earlier because the tablet must supply 5V VBUS
	 * and nothing switches it. NOTE: VBUS on this device is NOT pmic_glink —
	 * it is the MAX77705 companion PMIC's OTG boost (charger @ i2c5 0x69,
	 * CHG_CNFG_00 mode field; see the &i2c5 comment). Until that regulator
	 * is driven, a SELF-POWERED hub sidesteps
	 * that entirely: it powers its own downstream ports and presents its
	 * D+ pull-up to us, so enumeration can proceed without us sourcing VBUS.
	 * That makes USB ethernet (r8152/ax88179/cdc_ether, all built as
	 * modules) and USB HID keyboards reachable -> DHCP via NetworkManager
	 * -> ssh, which is the fastest route to a real shell.
	 *
	 * Switch back to "peripheral" for USB gadget/networking-to-PC, but note
	 * that direction likely needs pmic_glink too (dwc3 needs VBUS DETECTION
	 * before it enables its D+ pullup).
	 */
	dr_mode = "host";
	maximum-speed = "high-speed";

	/* USB 2.0 only — do not reference the disabled SuperSpeed phy. */
	phys = <&usb_1_hsphy>;
	phy-names = "usb2-phy";

	/*
	 * Do NOT /delete-node/ ports here: usb_1_qmpphy's port@1 endpoint has
	 * remote-endpoint = <&usb_1_dwc3_ss>, and dtc validates phandles even
	 * for disabled nodes, so removing the label fails the build with
	 *   ERROR (phandle_references): ... non-existent node or label
	 *   "usb_1_dwc3_ss"
	 * Leaving the graph in place is harmless — the kernel ignores the link
	 * because usb_1_qmpphy is disabled and we no longer list it in phys.
	 */
};

&usb_1_hsphy {
	vdda-pll-supply = <&vreg_l5b_0p88>;
	vdda18-supply = <&vreg_l1c_1p8>;
	vdda33-supply = <&vreg_l2b_3p07>;

	status = "okay";
};

/*
 * Debug UART. sm8450.dtsi leaves uart7 (qcom,geni-debug-uart @ 0x99c000)
 * status="disabled", so console=ttyMSM0 in our bootargs was binding to nothing
 * and only earlycon (which bypasses the DT node) ever produced output. This is
 * the same UART the stock DTB names in stdout-path.
 */
/*
 * QUP wrappers. On Qualcomm the serial/i2c/spi nodes are CHILDREN of a
 * "geniqup" wrapper, and sm8450.dtsi leaves every wrapper disabled. Enabling
 * only the leaf node does nothing — the child never probes, silently.
 *
 * Confirmed on-device: with just &uart7 and &i2c18 set to okay,
 * /sys/bus/i2c/devices/ was EMPTY and /proc/consoles listed only tty0.
 *
 *   qupv3_id_0 (geniqup@9c0000) -> uart7  (serial@99c000, debug UART)
 *   qupv3_id_2 (geniqup@8c0000) -> i2c18  (i2c@88c000, pogo keyboard STM32)
 */
&qupv3_id_0 {
	status = "okay";
};

&qupv3_id_2 {
	status = "okay";
};

/*
 * Touchscreen: STMicro FingerTip FTS1BA90A.
 *
 * IT IS ON I2C, NOT SPI. The kernel-src fts_spi/ directory is a red herring —
 * every SPI SE in the stock DTB is status="disabled", including qupv3_se8_spi
 * which is the SAME serial engine at 0xa80000 in its other mode.
 *
 * Bus identification is solid: stock qupv3_se8_i2c is i2c@a80000 with
 * interrupts <0 0x161 4>; 0x161 = 353, and mainline sm8450.dtsi i2c8 is
 * i2c@a80000 with GIC_SPI 353. Same controller. Its wrapper is qupv3_id_1
 * (geniqup@ac0000), which MUST be enabled too — enabling the leaf alone
 * silently does nothing (the QUP trap that cost us a boot cycle on i2c18).
 *
 * Stock node (stock-fdt.dts:14647) is compatible = "stm,fts_touch", a Samsung
 * downstream binding. We drive it with our own fts1ba90a.c port (staged into
 * drivers/input/touchscreen/ by the kernel APKBUILD), compatible
 * "st,fts1ba90a". Mainline's st,stmfts was tried first and is RULED OUT:
 * FTS1BA90A speaks 16-byte events with opcodes 0x60/0x61 (read events) /
 * 0x10/0x11 (sense on/off), stmfts expects 8-byte events and 0x85/0x86/
 * 0x92/0x93 — it failed to probe with -110 (no interrupt after sense-on,
 * because the command meant something else to this firmware).
 *
 * Property renames from stock to our binding:
 *   sec,irq_gpio <&tlmm 46>  -> interrupts (mainline needs a real interrupt;
 *                               downstream synthesised one with gpio_to_irq)
 *   tsp_avdd_ldo-supply      -> avdd-supply  (pm8350c L7C, 3.3 V)
 *   tsp_io_ldo-supply        -> vdd-supply   (pm8350c L8C, 1.848 V)
 *   sec,max_coords <1752 2800> -> touchscreen-size-x/y
 *
 */
/*
 * GPI DMA engine for QUP wrapper 1. i2c8 declares
 *     dmas = <&gpi_dma1 0 0 QCOM_GPI_I2C>, <&gpi_dma1 1 0 QCOM_GPI_I2C>;
 * and sm8450.dtsi ships gpi_dma1 status="disabled", so geni_i2c could never
 * get a channel and never probed. See the &i2c8 comment for how that cascaded
 * into "failed to mount subpartitions".
 */
&gpi_dma1 {
	status = "okay";
};

/*
 * i2c5 hosts the MAX77705 Samsung companion PMIC (stock qupv3_se5_i2c):
 * top/sys @0x66 (the DT reg), MUIC @0x25, charger @0x69, fuel gauge @0x36.
 * This is the chip that owns Type-C, VBUS sourcing (OTG boost) and charging.
 * Bus enabled first for register-level verification from userspace; the
 * OTG-boost regulator driver comes next (docs/07 open threads). Same QUP
 * plumbing rules as i2c8: wrapper (qupv3_id_0) and GPI DMA (gpi_dma0) must
 * both be enabled or the leaf silently never probes.
 */
&gpi_dma0 {
	status = "okay";
};

&qupv3_id_0 {
	status = "okay";
};

&i2c5 {
	status = "okay";

	/*
	 * Minimal OTG-boost-only driver at the charger client address (see
	 * max77705-otg.c). Verified live before the driver existed: writing
	 * the CHG_CNFG_00 mode nibble 0x05 -> 0x0F sourced VBUS and a
	 * bus-powered HID keyboard enumerated. The full MFD (charging
	 * policy, fuel gauge, MUIC, PD) is deliberately NOT described.
	 */
	charger@69 {
		compatible = "samsung,max77705-otg";
		reg = <0x69>;

		max77705_otg_vbus: otg-vbus {
			regulator-name = "usb_otg_vbus";
		};
	};
};

&qupv3_id_1 {
	status = "okay";
};

&i2c8 {
	/*
	 * i2c8 NEEDS ITS GPI DMA CONTROLLER ENABLED (see &gpi_dma1 below).
	 *
	 * Enabling this bus is what broke boot, and the path was indirect:
	 * geni_i2c could not probe, sat in deferred probe, and a device stuck
	 * in deferred probe blocks interconnect sync_state:
	 *     platform a80000.i2c: deferred probe pending:
	 *         geni_i2c: Failed to setup GPI DMA mode
	 *     qnoc-sm8450 interconnect-1:       sync_state() pending due to a80000.i2c
	 *     qnoc-sm8450 1700000.interconnect: sync_state() pending due to a80000.i2c
	 *     ...and two more providers
	 * sync_state finalises the NoC bandwidth votes for the whole SoC,
	 * including the path to storage, so UFS came up too late and the
	 * initramfs gave up hunting subpartitions after its 10 s window. The
	 * symptom ("failed to mount subpartitions") named storage; the cause
	 * was a touchscreen bus waiting on a DMA engine.
	 *
	 * DEAD END, DO NOT REPEAT: deleting dmas/dma-names to force PIO makes
	 * it WORSE. The driver then fails outright rather than deferring:
	 *     geni_i2c a80000.i2c: error -ENODEV: Failed to get tx DMA ch
	 *     geni_i2c a80000.i2c: error -ENODEV: Failed to setup GPI DMA mode
	 * Note the working i2c18 KEEPS its dmas property, so the phandle has to
	 * be there. Give the bus a real controller instead.
	 */
	clock-frequency = <400000>;
	status = "okay";

	touchscreen@49 {
		compatible = "st,fts1ba90a";
		reg = <0x49>;

		/*
		 * Stock declares no interrupts property at all, only
		 * sec,irq_gpio = <&tlmm 46 0>. That 0 is a GPIO flag, NOT an
		 * IRQ trigger type, so it is no evidence of polarity.
		 * LEVEL_LOW is the FingerTip convention — if the driver probes
		 * but never receives events, try IRQ_TYPE_EDGE_FALLING here
		 * before suspecting anything else.
		 */
		interrupt-parent = <&tlmm>;
		interrupts = <46 IRQ_TYPE_LEVEL_LOW>;

		pinctrl-names = "default";
		pinctrl-0 = <&ts_irq_default>;

		avdd-supply = <&vreg_l7c_3p3>;
		vdd-supply = <&vreg_l8c_1p8>;

		/*
		 * Touch reports PORTRAIT 1752x2800 while our framebuffer scans
		 * out LANDSCAPE 2800x1752, so the axes are swapped.
		 *
		 * The inversion is MEASURED, not guessed: with swap-only, taps
		 * on an upper-left -> lower-right diagonal produced
		 * anti-correlated coordinates (upper-left = x 21..92 with
		 * y 1611..1691 near the 1751 max, lower-right = x 2047 with
		 * y 484), i.e. exactly one axis flipped, with the visual top
		 * edge at the RAW X maximum.
		 *
		 * Why inverted-X for a vertical flip: drivers/input/
		 * touchscreen.c applies inversion BEFORE the swap, so the
		 * flags name RAW (portrait) axes. Raw X (the 1752 axis)
		 * becomes the on-screen vertical after the swap, and raw X is
		 * the axis that read backwards. (The Wacom sibling's
		 * wacom,invert = <0 1 1> "y" hint refers to Samsung's
		 * post-rotation frame — same physical flip, different name.)
		 */
		touchscreen-size-x = <1752>;
		touchscreen-size-y = <2800>;
		touchscreen-swapped-x-y;
		touchscreen-inverted-x;
	};
};

/*
 * S Pen — Wacom W90xx EMR digitizer, i2c 0x56 on QUP se14 (&i2c14, pins
 * gpio52/53). Mapped from the stock DTB (qupv3_se14_i2c: i2c@a98000 ->
 * wacom@56). SE14 shares the QUP1 wrapper with the working touch bus
 * (&i2c8), so the GPI-DMA deferred-probe cascade that plagued i2c8 bring-up
 * does not re-apply here — that wrapper's DMA engine is already up.
 *
 * There is no mainline driver for this Samsung EMR part yet (the downstream
 * driver lives in kernel-src/drivers/input/wacom/). This node is staged for
 * the PROBE-FIRST milestone: with AVDD always-on (wacom_avdd) the chip
 * should ACK at 0x56 under `i2cdetect -y -r <bus>` even before a driver
 * exists. Wiring transcribed from the stock wacom@56:
 *   irq  -> &tlmm 51  (epen-int,  input, level-low)
 *   fwe  -> &tlmm 54  (epen-fwe,  flash-enable, driver-owned)
 *   pdct -> &tlmm 155 (epen-pdct, pen-detect, input)
 *   avdd -> wacom_avdd (tlmm 167 fixed reg)
 *   firmware wez01_gts8p.bin (harvested; tools/fw-manifest.tsv)
 */
&i2c14 {
	clock-frequency = <400000>;
	status = "okay";

	wacom@56 {
		compatible = "wacom,w90xx";
		reg = <0x56>;

		interrupt-parent = <&tlmm>;
		interrupts = <51 IRQ_TYPE_LEVEL_LOW>;

		pinctrl-names = "default";
		pinctrl-0 = <&wacom_irq_default>, <&wacom_pdct_default>;

		vdd-supply = <&wacom_avdd>;

		wacom,irq-gpio = <&tlmm 51 GPIO_ACTIVE_LOW>;
		wacom,fwe-gpio = <&tlmm 54 GPIO_ACTIVE_HIGH>;
		wacom,pdct-gpio = <&tlmm 155 GPIO_ACTIVE_LOW>;
		wacom,fw_path = "wez01_gts8p.bin";
	};
};

&uart7 {
	status = "okay";
};

/*
 * WiFi: WCN6855 on PCIe0 (ath11k_pci). The wcn6855-pmu node (power
 * sequencing) plus PCI pwrctl handle bring-up; pcie0's PERST/clkreq
 * pinctrl comes from sm8450.dtsi. Stock BT UART is confirmed the same SE
 * as the HDK: hsuart0 = qup_uart@894000 = mainline uart20, pins 76-79.
 * uart20's wrapper is qupv3_id_2 — which must be enabled too (QUP trap).
 */
/*
 * Native display: MSM DPU + DSI + our S6TUUM1 panel driver
 * (panel-samsung-s6tuum1.c; extraction in device-facts/display-s6tuum1.md).
 * Command mode, DSC 1.1. Wiring per sm8450-hdk; supplies per HDK (dsi vdda
 * = l6b 1.2 V, phy vdds = l5b 0.88 V — both already declared for UFS/USB).
 *
 * The simple-framebuffer chosen node stays: simpledrm carries the console
 * until msm probes, then the aperture helper evicts it and fbcon migrates
 * to the DRM device. If the panel driver fails, the screen goes dark but
 * WiFi ssh survives — and reverting to pure simpledrm is one status flip.
 * clk/pd_ignore_unused stay in bootargs until this path is proven.
 */
&mdss {
	status = "okay";
};

&mdss_dsi0 {
	vdda-supply = <&vreg_l6b_1p2>;
	status = "okay";

	panel: panel@0 {
		compatible = "samsung,s6tuum1-amsa24vu01";
		reg = <0>;

		vdd-supply = <&panel_ldo>;
		reset-gpios = <&tlmm 0 GPIO_ACTIVE_HIGH>;
		/* Anapass TCON boot-done pin (stock samsung,tcon-rdy-gpio) */
		tcon-rdy-gpios = <&tlmm 1 GPIO_ACTIVE_HIGH>;

		pinctrl-names = "default";
		pinctrl-0 = <&disp_te_default>;

		port {
			panel_in: endpoint {
				remote-endpoint = <&mdss_dsi0_out>;
			};
		};
	};
};

&mdss_dsi0_out {
	remote-endpoint = <&panel_in>;
	data-lanes = <0 1 2 3>;
};

&mdss_dsi0_phy {
	vdds-supply = <&vreg_l5b_0p88>;
	status = "okay";
};

&pcie0 {
	status = "okay";
	max-link-speed = <2>;
};

&pcie0_phy {
	status = "okay";
	vdda-phy-supply = <&vreg_l5b_0p88>;
	vdda-pll-supply = <&vreg_l6b_1p2>;
};

&pcieport0 {
	wifi@0 {
		compatible = "pci17cb,1103";
		reg = <0x10000 0x0 0x0 0x0 0x0>;

		vddrfacmn-supply = <&vreg_pmu_rfa_cmn_0p8>;
		vddaon-supply = <&vreg_pmu_aon_0p8>;
		vddwlcx-supply = <&vreg_pmu_wlcx_0p8>;
		vddwlmx-supply = <&vreg_pmu_wlmx_0p8>;
		vddpcie1p8-supply = <&vreg_pmu_pcie_1p8>;
		vddpcie0p9-supply = <&vreg_pmu_pcie_0p9>;
		vddrfa0p8-supply = <&vreg_pmu_rfa_0p8>;
		vddrfa1p2-supply = <&vreg_pmu_rfa_1p2>;
		vddrfa1p8-supply = <&vreg_pmu_rfa_1p7>;
	};
};

&qupv3_id_2 {
	status = "okay";
};

&uart20 {
	pinctrl-0 = <&uart20_default>;
	pinctrl-names = "default";
	status = "okay";

	bluetooth {
		compatible = "qcom,wcn6855-bt";

		vddrfacmn-supply = <&vreg_pmu_rfa_cmn_0p8>;
		vddaon-supply = <&vreg_pmu_aon_0p8>;
		vddwlcx-supply = <&vreg_pmu_wlcx_0p8>;
		vddwlmx-supply = <&vreg_pmu_wlmx_0p8>;
		vddbtcmx-supply = <&vreg_pmu_btcmx_0p8>;
		vddrfa0p8-supply = <&vreg_pmu_rfa_0p8>;
		vddrfa1p2-supply = <&vreg_pmu_rfa_1p2>;
		vddrfa1p7-supply = <&vreg_pmu_rfa_1p7>;
	};
};

/*
 * Buttons. These are the ONLY input devices that work today (no touchscreen
 * driver, pogo keyboard unported, USB dead), and they are free: mainline
 * already has the drivers, pmk8350.dtsi already declares the nodes with the
 * same interrupts the stock DTB uses — they are merely disabled by default.
 *
 * This matters more than it looks: the pmOS initramfs polls
 *   iskey KEY_LEFTCTRL KEY_VOLUMEDOWN -> debug shell
 * so a working volume-down key gives an interactive boot-time debug shell
 * with no new driver code at all.
 *
 * Volume UP is a separate gpio-keys line on pm8350 gpio6 (stock DTB); not
 * wired up yet since volume-down alone unlocks the debug shell.
 */
/*
 * Software route into Samsung download (Odin) mode: ABL checks the PON
 * SOFT_RB_SPARE restart-reason at boot, and the downstream kernel's
 * `reboot download` writes 0x15 there (sec_qc_rbcmd_command.c,
 * PON_RESTART_REASON_DOWNLOAD). Mainline's qcom-pon driver provides the
 * same write via the reboot-mode framework with the same bit shift, so
 * this one property makes `reboot <arg>=download` (RESTART2 syscall)
 * land the device in download mode — no volume-key dance. Userspace
 * helper: reboot-download (busybox reboot cannot pass the argument).
 */
&pmk8350_pon {
	mode-download = <0x15>;
};

&pon_pwrkey {
	status = "okay";
};

&pon_resin {
	linux,code = <KEY_VOLUMEDOWN>;
	status = "okay";
};

/*
 * GPU: Adreno 730. sm8450.dtsi carries the full gpu/gmu/smmu description;
 * per-board all that's needed is the zap shader. Samsung ships NO zap in
 * vendor/ — the signed image lives in the apnhlos partition as split
 * a730_zap.mdt + .b00-.b02 (found by mounting apnhlos on-device; staged
 * into /lib/firmware/qcom/sm8450/gts8pwifi/). qcom_mdt_load handles the
 * split format natively. SQE + GMU firmware come from linux-firmware
 * (a730_sqe.fw.zst / gmu_gen70000.bin.zst — FW_LOADER_COMPRESS_ZSTD is
 * enabled and proven by ath11k).
 */
&gpu {
	status = "okay";

	zap-shader {
		firmware-name = "qcom/sm8450/gts8pwifi/a730_zap.mdt";
	};
};
